# CH579SFR register map
Vendor: WCH Ltd.; Series: CH57x; File version: 1.0
WCH wireless MCU CH57x Family Support, Drivers
CPU: CM0 r0p0, little endian, no MPU, no FPU, 2 interrupt priority bits
Registers are 8-bit, read-write, reset 0x0 unless marked. A register's access mark holds for its fields unless they carry their own. Offsets are from the block's base; lines under a group give offsets from that group; [hi:lo] are bit positions; {n}, {i} and the like mark numbered series; 'fields as' and 'values as' point back to an identical list; <NAME> marks a mode.

## Memory map
0x40001000 SYS size 0x400 — System Control Register
0x40001800 FLASH size 0x400 — Flash ROM control register
0x40002000 TMR0 size 0x400 — Timer0 register
0x40002400 TMR1 size 0x400 — Timer1 register
0x40002800 TMR2 size 0x400 — Timer2 register
0x40002C00 TMR3 size 0x400 — Timer3 register
0x40003000 UART0 size 0x400
0x40003400 UART1 size 0x400
0x40003800 UART2 size 0x400
0x40003C00 UART3 size 0x400
0x40004000 SPI0 size 0x400
0x40004400 SPI1 size 0x400
0x40005000 PWMx size 0x400
0x40006000 LCD size 0x400
0x40006400 LED size 0x400
0x40008000 USB size 0x400
0x40009000 ETH size 0x400

## Interrupts
0 TMR0 — TMR0_IRQHandler
1 GPIO (SYS) — GPIO_IRQHandler
2 SLAVE (SYS) — SLAVE_IRQHandler
3 SPI0 — SPI0_IRQHandler
4 BB (SYS) — BB_IRQHandler
5 LLE (SYS) — LLE_IRQHandler
6 USB — USB_IRQHandler
7 ETH — ETH_IRQHandler
8 TMR1 — TMR1_IRQHandler
9 TMR2 — TMR2_IRQHandler
10 UART0 — UART0_IRQHandler
11 UART1 — UART1_IRQHandler
12 RTC (SYS) — RTC_IRQHandler
13 ADC (SYS) — ADC_IRQHandler
14 SPI1 — SPI1_IRQHandler
15 LED — LED_IRQHandler
16 TMR3 — TMR3_IRQHandler
17 UART2 — UART1_IRQHandler
18 UART3 — UART3_IRQHandler
19 WDOG_BAT (SYS) — WDT_IRQHandler

## FLASH — Flash ROM control register
Base 0x40001800
0x00 R32_FLASH_DATA 32-bit — RW, Flash ROM data
0x04 R32_FLASH_ADDR 32-bit — RW, Flash ROM address
0x08 R8_FLASH_COMMAND wo — WO, Flash ROM operation command
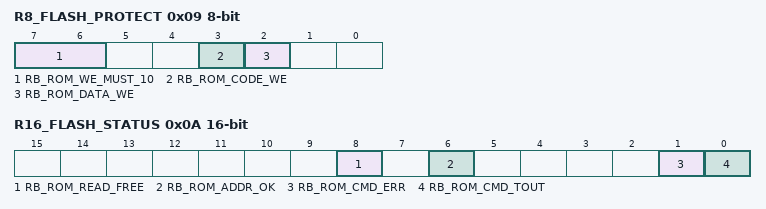
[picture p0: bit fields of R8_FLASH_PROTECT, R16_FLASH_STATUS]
0x09 R8_FLASH_PROTECT — RW, Flash ROM protect control
  [7:6] RB_ROM_WE_MUST_10 wo — RW, must write 10
  [3] RB_ROM_CODE_WE — RW, enable Flash ROM code area being erase/write: 0=writing protect, 1=enable program and erase
  [2] RB_ROM_DATA_WE — RW, enable Flash ROM data area being erase/write: 0=writing protect, 1=enable program and erase
0x0A R16_FLASH_STATUS 16-bit ro — RO, Flash ROM operation status
  [8] RB_ROM_READ_FREE — RO, indicate protected status of Flash ROM code and data: 0=reading protect, 1=enable read by external programmer
  [6] RB_ROM_ADDR_OK — RO, Flash ROM erase/write operation address valid flag, can be reviewed before or after operation: 0=invalid parameter, 1=address valid
  [1] RB_ROM_CMD_ERR — RO, Flash ROM operation command error flag: 0=command accepted, 1=unknown command
  [0] RB_ROM_CMD_TOUT — RO, Flash ROM operation result: 0=success, 1=operation time out

## TMR0 — Timer0 register
Base 0x40002000
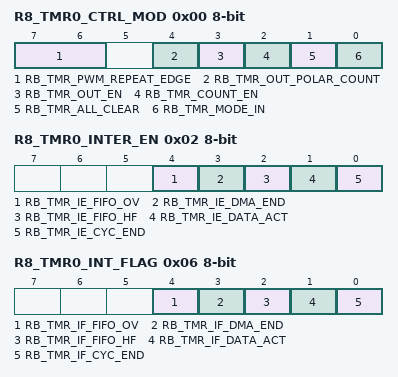
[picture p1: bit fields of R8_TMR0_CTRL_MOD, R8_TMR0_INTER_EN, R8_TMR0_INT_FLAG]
0x00 R8_TMR0_CTRL_MOD — RW, TMR0 mode control
  [7:6] RB_TMR_PWM_REPEAT_EDGE — RW, timer PWM repeat mode: 00=1, 01=4, 10=8, 11-16;RW, timer capture edge mode: 00=disable, 01=edge change, 10=fall to fall, 11-rise to rise
  [4] RB_TMR_OUT_POLAR_COUNT — RW, timer PWM output polarity: 0=default low and high action, 1=default high and low action;RW, count sub-mode if RB_TMR_MODE_IN=1: 0=capture, 1=count
  [3] RB_TMR_OUT_EN — RW, timer output enable
  [2] RB_TMR_COUNT_EN — RW, timer count enable
  [1] RB_TMR_ALL_CLEAR — RW, force clear timer FIFO and count
  [0] RB_TMR_MODE_IN — RW, timer in mode: 0=timer/PWM, 1=capture/count
0x02 R8_TMR0_INTER_EN — RW, TMR0 interrupt enable
  [4] RB_TMR_IE_FIFO_OV — RW, enable interrupt for timer FIFO overflow
  [3] RB_TMR_IE_DMA_END — RW, enable interrupt for timer1/2 DMA completion
  [2] RB_TMR_IE_FIFO_HF — RW, enable interrupt for timer FIFO half (capture fifo >=4 or PWM fifo less than 3)
  [1] RB_TMR_IE_DATA_ACT — RW, enable interrupt for timer capture input action or PWM trigger
  [0] RB_TMR_IE_CYC_END — RW, enable interrupt for timer capture count timeout or PWM cycle end
0x06 R8_TMR0_INT_FLAG — RW1, TMR0 interrupt flag
  [4] RB_TMR_IF_FIFO_OV — RW1, interrupt flag for timer FIFO overflow
  [3] RB_TMR_IF_DMA_END — RW1, interrupt flag for timer1/2 DMA completion
  [2] RB_TMR_IF_FIFO_HF — RW1, interrupt flag for timer FIFO half (capture fifo >=4 or PWM fifo less than 3
  [1] RB_TMR_IF_DATA_ACT — RW1, interrupt flag for timer capture input action or PWM trigger
  [0] RB_TMR_IF_CYC_END — RW1, interrupt flag for timer capture count timeout or PWM cycle end
0x07 R8_TMR0_FIFO_COUNT ro — RO, TMR0 FIFO count status
0x08 R32_TMR0_COUNT 32-bit ro — RO, TMR0 current count
0x0C R32_TMR0_CNT_END 32-bit — RW, TMR0 end count value, only low 26 bit
0x10 R32_TMR0_FIFO_RO 32-bit ro — RO, TMR0 FIFO register, only low 26 bit
0x10 R32_TMR0_FIFO_WO 32-bit wo — WO, TMR0 FIFO register, only low 26 bit

## TMR1 — Timer1 register
Base 0x40002400
Registers as TMR0 (with TMR0 read as TMR1); these are added or differ:
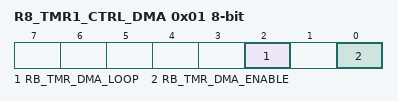
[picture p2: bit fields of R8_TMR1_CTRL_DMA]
0x01 R8_TMR1_CTRL_DMA — RW, TMR1 DMA control
  [2] RB_TMR_DMA_LOOP — RW, timer1/2 DMA address loop enable
  [0] RB_TMR_DMA_ENABLE — RW, timer1/2 DMA enable
0x14 R16_TMR1_DMA_NOW 16-bit ro — RO, TMR1 DMA current address
0x18 R16_TMR1_DMA_BEG 16-bit — RW, TMR1 DMA begin address
0x1C R16_TMR1_DMA_END 16-bit — RW, TMR1 DMA end address

## TMR2 — Timer2 register
Base 0x40002800
Registers as TMR1 (with TMR1 read as TMR2).

## TMR3 — Timer3 register
Base 0x40002C00
Registers as TMR0 (with TMR0 read as TMR3).
